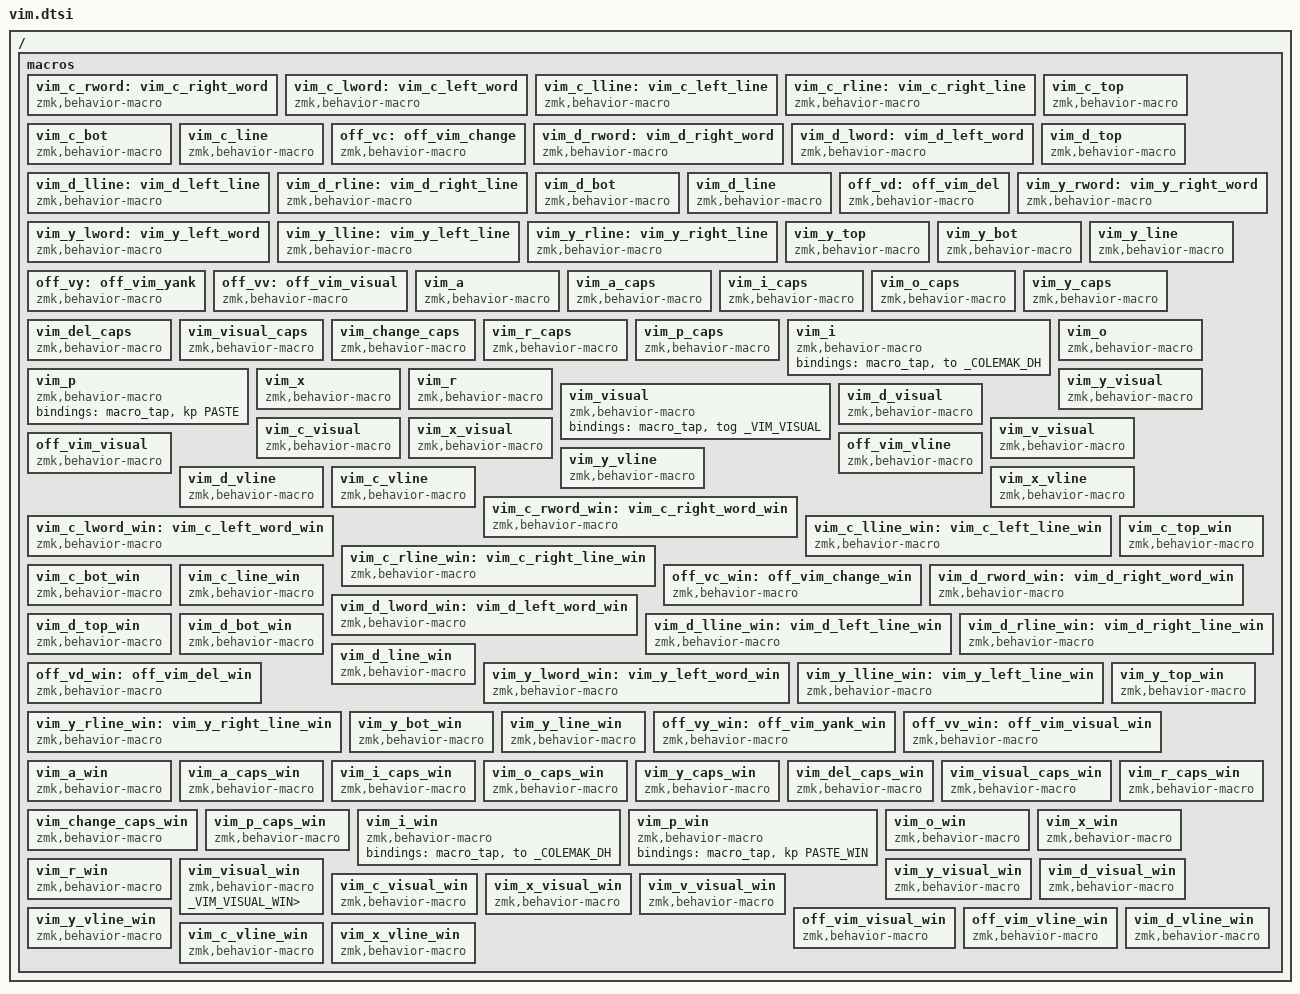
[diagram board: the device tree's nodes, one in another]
#define VLINE_UP LA(LS(UP))
#define VLINE_DOWN LA(LS(DOWN))

#define V_TOP LG(UP)
#define V_BOT LG(DOWN)

// WINDOWS vim section
#define SEARCH_WIN LC(F)

#define WORD_L_WIN LC(LEFT)
#define WORD_R_WIN LC(RIGHT)
#define WORD_L_SEL_WIN LC(LS(LEFT))
#define WORD_R_SEL_WIN LC(LS(RIGHT))

#define DEL_WORD_WIN LC(BSPC)
#define F_LINE_WIN HOME
#define L_LINE_WIN END

#define F_LINE_SEL_WIN LC(LS(HOME))
#define L_LINE_SEL_WIN LC(LS(END))

#define C_COPY_WIN LC(C)
#define PASTE_WIN LC(V)
#define C_CUT_WIN LC(X)
#define C_UNDO_WIN LC(Z)
#define C_REDO_WIN LC(LS(Z))

#define VLINE_UP_WIN LC(LS(UP))
#define VLINE_DOWN_WIN LC(LS(DOWN))

#define V_TOP_WIN LC(HOME)
#define V_BOT_WIN LC(END)
// end WINDOWS vim section

/ {

  macros {
  
    // vim CHANGE mode
    /omit-if-no-ref/ vim_c_rword: vim_c_right_word {
      wait-ms = <0>;
      tap-ms = <0>;
      compatible = "zmk,behavior-macro";
      #binding-cells = <0>;
      bindings = <&macro_tap &kp WORD_R_SEL>,
        <&macro_tap &kp BSPC>,
        <&macro_tap &to _COLEMAK_DH>;
    };

    /omit-if-no-ref/ vim_c_lword: vim_c_left_word {
      wait-ms = <0>;
      tap-ms = <0>;
      compatible = "zmk,behavior-macro";
      #binding-cells = <0>;
      bindings = <&macro_tap &kp WORD_L_SEL>,
        <&macro_tap &kp BSPC>,
        <&macro_tap &to _COLEMAK_DH>;
    };

    /omit-if-no-ref/ vim_c_lline: vim_c_left_line {
      wait-ms = <0>;
      tap-ms = <0>;
      compatible = "zmk,behavior-macro";
      #binding-cells = <0>;
      bindings = <&macro_tap &kp F_LINE_SEL>,
        <&macro_tap &kp BSPC>,
        <&macro_tap &to _COLEMAK_DH>;
    };

    /omit-if-no-ref/ vim_c_rline: vim_c_right_line {
      wait-ms = <0>;
      tap-ms = <0>;
      compatible = "zmk,behavior-macro";
      #binding-cells = <0>;
      bindings = <&macro_tap &kp L_LINE_SEL>,
        <&macro_tap &kp BSPC>,
        <&macro_tap &to _COLEMAK_DH>;
    };

    /omit-if-no-ref/ vim_c_top: vim_c_top {
      wait-ms = <0>;
      tap-ms = <0>;
      compatible = "zmk,behavior-macro";
      #binding-cells = <0>;
      bindings = <&macro_tap &kp VLINE_UP>,
        <&macro_tap &kp BSPC>,
        <&macro_tap &to _COLEMAK_DH>;
    };

    /omit-if-no-ref/ vim_c_bot: vim_c_bot {
      wait-ms = <0>;
      tap-ms = <0>;
      compatible = "zmk,behavior-macro";
      #binding-cells = <0>;
      bindings = <&macro_tap &kp VLINE_DOWN>,
        <&macro_tap &kp BSPC>,
        <&macro_tap &to _COLEMAK_DH>;
    };

    /omit-if-no-ref/ vim_c_line: vim_c_line {
      wait-ms = <0>;
      tap-ms = <0>;
      compatible = "zmk,behavior-macro";
      #binding-cells = <0>;
      bindings = <&macro_tap &kp F_LINE>,
        <&macro_tap &kp L_LINE_SEL>,
        <&macro_tap &kp BSPC>,
        <&macro_tap &to _COLEMAK_DH>;
    };

    /omit-if-no-ref/ off_vc: off_vim_change {
      wait-ms = <0>;
      tap-ms = <0>;
      compatible = "zmk,behavior-macro";
      #binding-cells = <0>;
      bindings = <&macro_tap &tog _VIM_CHANGE>;
    };

    // vim DEL mode
    /omit-if-no-ref/ vim_d_rword: vim_d_right_word {
      wait-ms = <0>;
      tap-ms = <0>;
      compatible = "zmk,behavior-macro";
      #binding-cells = <0>;
      bindings = <&macro_tap &kp WORD_R_SEL>,
        <&macro_tap &kp BSPC>;
    };

    /omit-if-no-ref/ vim_d_lword: vim_d_left_word {
      wait-ms = <0>;
      tap-ms = <0>;
      compatible = "zmk,behavior-macro";
      #binding-cells = <0>;
      bindings = <&macro_tap &kp WORD_L_SEL>,
        <&macro_tap &kp BSPC>;
    };

    /omit-if-no-ref/ vim_d_lline: vim_d_left_line {
      wait-ms = <0>;
      tap-ms = <0>;
      compatible = "zmk,behavior-macro";
      #binding-cells = <0>;
      bindings = <&macro_tap &kp F_LINE_SEL>,
        <&macro_tap &kp BSPC>;
    };

    /omit-if-no-ref/ vim_d_rline: vim_d_right_line {
      wait-ms = <0>;
      tap-ms = <0>;
      compatible = "zmk,behavior-macro";
      #binding-cells = <0>;
      bindings = <&macro_tap &kp L_LINE_SEL>,
        <&macro_tap &kp BSPC>;
    };

    /omit-if-no-ref/ vim_d_top: vim_d_top {
      wait-ms = <0>;
      tap-ms = <0>;
      compatible = "zmk,behavior-macro";
      #binding-cells = <0>;
      bindings = <&macro_tap &kp VLINE_UP>,
        <&macro_tap &kp BSPC>;
    };

    /omit-if-no-ref/ vim_d_bot: vim_d_bot {
      wait-ms = <0>;
      tap-ms = <0>;
      compatible = "zmk,behavior-macro";
      #binding-cells = <0>;
      bindings = <&macro_tap &kp VLINE_DOWN>,
        <&macro_tap &kp BSPC>;
    };


    /omit-if-no-ref/ vim_d_line: vim_d_line {
      wait-ms = <0>;
      tap-ms = <0>;
      compatible = "zmk,behavior-macro";
      #binding-cells = <0>;
      bindings = <&macro_tap &kp F_LINE>,
        <&macro_tap &kp L_LINE_SEL>,
        <&macro_tap &kp BSPC>;
    };

    /omit-if-no-ref/ off_vd: off_vim_del {
      wait-ms = <0>;
      tap-ms = <0>;
      compatible = "zmk,behavior-macro";
      #binding-cells = <0>;
      bindings = <&macro_tap &tog _VIM_DELETE>;
    };

    // vim YANK mode
    /omit-if-no-ref/ vim_y_rword: vim_y_right_word {
      wait-ms = <0>;
      tap-ms = <0>;
      compatible = "zmk,behavior-macro";
      #binding-cells = <0>;
      bindings = <&macro_tap &kp WORD_R_SEL>,
        <&macro_tap &kp C_COPY>,
        <&macro_tap &kp LEFT>;
    };

    /omit-if-no-ref/ vim_y_lword: vim_y_left_word {
      wait-ms = <0>;
      tap-ms = <0>;
      compatible = "zmk,behavior-macro";
      #binding-cells = <0>;
      bindings = <&macro_tap &kp WORD_L_SEL>,
        <&macro_tap &kp C_COPY>,
        <&macro_tap &kp LEFT>;
    };

    /omit-if-no-ref/ vim_y_lline: vim_y_left_line {
      wait-ms = <0>;
      tap-ms = <0>;
      compatible = "zmk,behavior-macro";
      #binding-cells = <0>;
      bindings = <&macro_tap &kp F_LINE_SEL>,
        <&macro_tap &kp C_COPY>,
        <&macro_tap &kp LEFT>;
    };

    /omit-if-no-ref/ vim_y_rline: vim_y_right_line {
      wait-ms = <0>;
      tap-ms = <0>;
      compatible = "zmk,behavior-macro";
      #binding-cells = <0>;
      bindings = <&macro_tap &kp L_LINE_SEL>,
        <&macro_tap &kp C_COPY>,
        <&macro_tap &kp LEFT>;
    };

    /omit-if-no-ref/ vim_y_top: vim_y_top {
      wait-ms = <0>;
      tap-ms = <0>;
      compatible = "zmk,behavior-macro";
      #binding-cells = <0>;
      bindings = <&macro_tap &kp VLINE_UP>,
        <&macro_tap &kp C_COPY>,
        <&macro_tap &kp LEFT>;
    };

    /omit-if-no-ref/ vim_y_bot: vim_y_bot {
      wait-ms = <0>;
      tap-ms = <0>;
      compatible = "zmk,behavior-macro";
      #binding-cells = <0>;
      bindings = <&macro_tap &kp VLINE_DOWN>,
        <&macro_tap &kp C_COPY>,
        <&macro_tap &kp LEFT>;
    };


    /omit-if-no-ref/ vim_y_line: vim_y_line {
      wait-ms = <0>;
      tap-ms = <0>;
      compatible = "zmk,behavior-macro";
      #binding-cells = <0>;
      bindings = <&macro_tap &kp F_LINE>,
        <&macro_tap &kp L_LINE_SEL>,
        <&macro_tap &kp C_COPY>,
        <&macro_tap &kp LEFT>;
    };

    /omit-if-no-ref/ off_vy: off_vim_yank {
      wait-ms = <0>;
      tap-ms = <0>;
      compatible = "zmk,behavior-macro";
      #binding-cells = <0>;
      bindings = <&macro_tap &tog _VIM_YANK>;
    };

    // vim VISUAL mode
    /omit-if-no-ref/ off_vv: off_vim_visual {
      wait-ms = <0>;
      tap-ms = <0>;
      compatible = "zmk,behavior-macro";
      #binding-cells = <0>;
      bindings = <&macro_tap &tog _VIM_VISUAL>;
    };


    /omit-if-no-ref/ vim_a: vim_a {
      compatible = "zmk,behavior-macro";
      #binding-cells = <0>;
      bindings 
      = <&macro_tap &kp RIGHT>
      ,<&macro_tap &to _COLEMAK_DH> 
      ;
    };

    /omit-if-no-ref/ vim_a_caps: vim_a_caps {
      compatible = "zmk,behavior-macro";
      #binding-cells = <0>;
      bindings 
      = <&macro_tap &kp L_LINE> 
      ,<&macro_tap &to _COLEMAK_DH> 
      ;
    };

    /omit-if-no-ref/ vim_i_caps: vim_i_caps {
      compatible = "zmk,behavior-macro";
      #binding-cells = <0>;
      bindings 
      = <&macro_tap &kp F_LINE> 
      ,<&macro_tap &to _COLEMAK_DH> 
      ;
    };

    /omit-if-no-ref/ vim_o_caps: vim_o_caps {
      compatible = "zmk,behavior-macro";
      #binding-cells = <0>;
      bindings 
      = <&macro_tap &kp F_LINE> 
      ,<&macro_tap &kp ENTER> 
      ,<&macro_tap &kp UP> 
      ,<&macro_tap &to _COLEMAK_DH> 
      ;
    };

    /omit-if-no-ref/ vim_y_caps: vim_y_caps {
      compatible = "zmk,behavior-macro";
      #binding-cells = <0>;
      bindings 
      = <&macro_tap &kp L_LINE_SEL> 
      ,<&macro_tap &kp C_COPY> 
      ,<&macro_tap &kp LEFT> 
      ;
    };

    /omit-if-no-ref/ vim_del_caps: vim_del_caps {
      compatible = "zmk,behavior-macro";
      #binding-cells = <0>;
      bindings 
      = <&macro_tap &kp L_LINE_SEL> 
      ,<&macro_tap &kp BSPC> 
      ;
    };

    /omit-if-no-ref/ vim_visual_caps: vim_visual_caps {
      compatible = "zmk,behavior-macro";
      #binding-cells = <0>;
      bindings = <&macro_tap &kp F_LINE>,
        <&macro_tap &kp L_LINE_SEL>,
        <&macro_tap &tog _VIM_VLINE>;
    };

    /omit-if-no-ref/ vim_change_caps: vim_change_caps {
      compatible = "zmk,behavior-macro";
      #binding-cells = <0>;
      bindings 
      = <&macro_tap &kp L_LINE_SEL> 
      ,<&macro_tap &kp BSPC> 
      ,<&macro_tap &to _COLEMAK_DH> 
      ;
    };

    /omit-if-no-ref/ vim_r_caps: vim_r_caps {
      compatible = "zmk,behavior-macro";
      #binding-cells = <0>;
      bindings 
      = <&macro_tap &kp INS> 
      ,<&macro_tap &to _COLEMAK_DH> 
      ;
    };

    /omit-if-no-ref/ vim_p_caps: vim_p_caps {
      compatible = "zmk,behavior-macro";
      #binding-cells = <0>;
      bindings 
      = <&macro_tap &kp F_LINE> 
      ,<&macro_tap &kp ENTER> 
      ,<&macro_tap &kp UP> 
      ,<&macro_tap &kp PASTE> 
      ;
    };

    /omit-if-no-ref/ vim_i: vim_i {
      compatible = "zmk,behavior-macro";
      #binding-cells = <0>;
      bindings 
      = <&macro_tap &to _COLEMAK_DH> 
      ;
    };

    /omit-if-no-ref/ vim_p: vim_p {
      compatible = "zmk,behavior-macro";
      #binding-cells = <0>;
      bindings 
      = <&macro_tap &kp PASTE> 
      ;
    };

    /omit-if-no-ref/ vim_o: vim_o {
      compatible = "zmk,behavior-macro";
      #binding-cells = <0>;
      bindings 
      = <&macro_tap &kp ENTER> 
      ,<&macro_tap &to _COLEMAK_DH> 
      ;
    };

    /omit-if-no-ref/ vim_x: vim_x {
      compatible = "zmk,behavior-macro";
      #binding-cells = <0>;
      bindings 
      = <&macro_tap &kp RIGHT>
      ,<&macro_tap &kp BSPC> 
      ;
    };

    /omit-if-no-ref/ vim_r: vim_r {
      compatible = "zmk,behavior-macro";
      #binding-cells = <0>;
      bindings 
      = <&macro_tap &kp RIGHT> 
      ,<&macro_tap &kp BSPC> 
      ,<&macro_tap &to _COLEMAK_DH> 
      ;
    };

    /omit-if-no-ref/ vim_visual: vim_visual {
      compatible = "zmk,behavior-macro";
      #binding-cells = <0>;
      bindings = <&macro_tap &tog _VIM_VISUAL>;
    };

    /omit-if-no-ref/ vim_y_visual: vim_y_visual {
      compatible = "zmk,behavior-macro";
      #binding-cells = <0>;
      bindings 
      = <&macro_tap &kp C_COPY>,
        <&macro_tap &kp LEFT>,
        <&macro_tap &tog _VIM_VISUAL>;
    };

    /omit-if-no-ref/ vim_d_visual: vim_d_visual {
      compatible = "zmk,behavior-macro";
      #binding-cells = <0>;
      bindings 
      = <&macro_tap &kp BSPC>,
        <&macro_tap &tog _VIM_VISUAL>;
    };

    /omit-if-no-ref/ vim_c_visual: vim_c_visual {
      compatible = "zmk,behavior-macro";
      #binding-cells = <0>;
      bindings 
      = <&macro_tap &kp BSPC>,
        <&macro_tap &to _COLEMAK_DH>;
    };

    /omit-if-no-ref/ vim_x_visual: vim_x_visual {
      compatible = "zmk,behavior-macro";
      #binding-cells = <0>;
      bindings 
      = <&macro_tap &kp C_CUT>,
        <&macro_tap &tog _VIM_VISUAL>;
    };

    /omit-if-no-ref/ vim_v_visual: vim_v_visual {
      compatible = "zmk,behavior-macro";
      #binding-cells = <0>;
      bindings 
      = <&macro_tap &kp LEFT>,
        <&macro_tap &kp RIGHT>,
        <&macro_tap &tog _VIM_VISUAL>;
    };

    /omit-if-no-ref/ off_vim_visual: off_vim_visual {
      compatible = "zmk,behavior-macro";
      #binding-cells = <0>;
      bindings 
      = <&macro_tap &kp LEFT>,
        <&macro_tap &kp RIGHT>,
        <&macro_tap &tog _VIM_VISUAL>;
    };

    /omit-if-no-ref/ off_vim_vline: off_vim_vline {
      compatible = "zmk,behavior-macro";
      #binding-cells = <0>;
      bindings 
      = <&macro_tap &kp LEFT>,
        <&macro_tap &kp RIGHT>,
        <&macro_tap &tog _VIM_VLINE>,
        <&macro_tap &tog _VIM_CAPS>;
    };

    /omit-if-no-ref/ vim_y_vline: vim_y_vline {
      compatible = "zmk,behavior-macro";
      #binding-cells = <0>;
      bindings 
      = <&macro_tap &kp C_COPY>,
        <&macro_tap &kp LEFT>,
        <&macro_tap &tog _VIM_VLINE>,
        <&macro_tap &tog _VIM_CAPS>;
    };

    /omit-if-no-ref/ vim_d_vline: vim_d_vline {
      compatible = "zmk,behavior-macro";
      #binding-cells = <0>;
      bindings 
      = <&macro_tap &kp DEL>,
        <&macro_tap &kp DEL>,
        <&macro_tap &tog _VIM_VLINE>,
        <&macro_tap &tog _VIM_CAPS>;
    };

    /omit-if-no-ref/ vim_c_vline: vim_c_vline {
      compatible = "zmk,behavior-macro";
      #binding-cells = <0>;
      bindings 
      = <&macro_tap &kp BSPC>,
        <&macro_tap &to _COLEMAK_DH>;
    };

    /omit-if-no-ref/ vim_x_vline: vim_x_vline {
      compatible = "zmk,behavior-macro";
      #binding-cells = <0>;
      bindings 
      = <&macro_tap &kp C_CUT>,
        <&macro_tap &tog _VIM_VLINE>,
        <&macro_tap &tog _VIM_CAPS>;
    };

    // WINDOWS VIM SECTION
    // vim WIN CHANGE mode
    /omit-if-no-ref/ vim_c_rword_win: vim_c_right_word_win {
      wait-ms = <0>;
      tap-ms = <0>;
      compatible = "zmk,behavior-macro";
      #binding-cells = <0>;
      bindings = <&macro_tap &kp WORD_R_SEL_WIN>,
        <&macro_tap &kp BSPC>,
        <&macro_tap &to _COLEMAK_DH>;
    };

    /omit-if-no-ref/ vim_c_lword_win: vim_c_left_word_win {
      wait-ms = <0>;
      tap-ms = <0>;
      compatible = "zmk,behavior-macro";
      #binding-cells = <0>;
      bindings = <&macro_tap &kp WORD_L_SEL_WIN>,
        <&macro_tap &kp BSPC>,
        <&macro_tap &to _COLEMAK_DH>;
    };

    /omit-if-no-ref/ vim_c_lline_win: vim_c_left_line_win {
      wait-ms = <0>;
      tap-ms = <0>;
      compatible = "zmk,behavior-macro";
      #binding-cells = <0>;
      bindings = <&macro_tap &kp F_LINE_SEL_WIN>,
        <&macro_tap &kp BSPC>,
        <&macro_tap &to _COLEMAK_DH>;
    };

    /omit-if-no-ref/ vim_c_rline_win: vim_c_right_line_win {
      wait-ms = <0>;
      tap-ms = <0>;
      compatible = "zmk,behavior-macro";
      #binding-cells = <0>;
      bindings = <&macro_tap &kp L_LINE_SEL_WIN>,
        <&macro_tap &kp BSPC>,
        <&macro_tap &to _COLEMAK_DH>;
    };

    /omit-if-no-ref/ vim_c_top_win: vim_c_top_win {
      wait-ms = <0>;
      tap-ms = <0>;
      compatible = "zmk,behavior-macro";
      #binding-cells = <0>;
      bindings = <&macro_tap &kp VLINE_UP_WIN>,
        <&macro_tap &kp BSPC>,
        <&macro_tap &to _COLEMAK_DH>;
    };

    /omit-if-no-ref/ vim_c_bot_win: vim_c_bot_win {
      wait-ms = <0>;
      tap-ms = <0>;
      compatible = "zmk,behavior-macro";
      #binding-cells = <0>;
      bindings = <&macro_tap &kp VLINE_DOWN_WIN>,
        <&macro_tap &kp BSPC>,
        <&macro_tap &to _COLEMAK_DH>;
    };

    /omit-if-no-ref/ vim_c_line_win: vim_c_line_win {
      wait-ms = <0>;
      tap-ms = <0>;
      compatible = "zmk,behavior-macro";
      #binding-cells = <0>;
      bindings = <&macro_tap &kp F_LINE_WIN>,
        <&macro_tap &kp L_LINE_SEL_WIN>,
        <&macro_tap &kp BSPC>,
        <&macro_tap &to _COLEMAK_DH>;
    };

    /omit-if-no-ref/ off_vc_win: off_vim_change_win {
      wait-ms = <0>;
      tap-ms = <0>;
      compatible = "zmk,behavior-macro";
      #binding-cells = <0>;
      bindings = <&macro_tap &tog _VIM_CHANGE_WIN>;
    };

    // vim DEL mode
    /omit-if-no-ref/ vim_d_rword_win: vim_d_right_word_win {
      wait-ms = <0>;
      tap-ms = <0>;
      compatible = "zmk,behavior-macro";
      #binding-cells = <0>;
      bindings = <&macro_tap &kp WORD_R_SEL_WIN>,
        <&macro_tap &kp BSPC>;
    };

    /omit-if-no-ref/ vim_d_lword_win: vim_d_left_word_win {
      wait-ms = <0>;
      tap-ms = <0>;
      compatible = "zmk,behavior-macro";
      #binding-cells = <0>;
      bindings = <&macro_tap &kp WORD_L_SEL_WIN>,
        <&macro_tap &kp BSPC>;
    };

    /omit-if-no-ref/ vim_d_lline_win: vim_d_left_line_win {
      wait-ms = <0>;
      tap-ms = <0>;
      compatible = "zmk,behavior-macro";
      #binding-cells = <0>;
      bindings = <&macro_tap &kp F_LINE_SEL_WIN>,
        <&macro_tap &kp BSPC>;
    };

    /omit-if-no-ref/ vim_d_rline_win: vim_d_right_line_win {
      wait-ms = <0>;
      tap-ms = <0>;
      compatible = "zmk,behavior-macro";
      #binding-cells = <0>;
      bindings = <&macro_tap &kp L_LINE_SEL_WIN>,
        <&macro_tap &kp BSPC>;
    };

    /omit-if-no-ref/ vim_d_top_win: vim_d_top_win {
      wait-ms = <0>;
      tap-ms = <0>;
      compatible = "zmk,behavior-macro";
      #binding-cells = <0>;
      bindings = <&macro_tap &kp VLINE_UP_WIN>,
        <&macro_tap &kp BSPC>;
    };

    /omit-if-no-ref/ vim_d_bot_win: vim_d_bot_win {
      wait-ms = <0>;
      tap-ms = <0>;
      compatible = "zmk,behavior-macro";
      #binding-cells = <0>;
      bindings = <&macro_tap &kp VLINE_DOWN_WIN>,
        <&macro_tap &kp BSPC>;
    };


    /omit-if-no-ref/ vim_d_line_win: vim_d_line_win {
      wait-ms = <0>;
      tap-ms = <0>;
      compatible = "zmk,behavior-macro";
      #binding-cells = <0>;
      bindings = <&macro_tap &kp F_LINE_WIN>,
        <&macro_tap &kp L_LINE_SEL_WIN>,
        <&macro_tap &kp BSPC>;
    };

    /omit-if-no-ref/ off_vd_win: off_vim_del_win {
      wait-ms = <0>;
      tap-ms = <0>;
      compatible = "zmk,behavior-macro";
      #binding-cells = <0>;
      bindings = <&macro_tap &tog _VIM_DELETE_WIN>;
    };

    // vim YANK mode
    /omit-if-no-ref/ vim_y_rword: vim_y_right_word {
      wait-ms = <0>;
      tap-ms = <0>;
      compatible = "zmk,behavior-macro";
      #binding-cells = <0>;
      bindings = <&macro_tap &kp WORD_R_SEL_WIN>,
        <&macro_tap &kp C_COPY_WIN>,
        <&macro_tap &kp LEFT>;
    };

    /omit-if-no-ref/ vim_y_lword_win: vim_y_left_word_win {
      wait-ms = <0>;
      tap-ms = <0>;
      compatible = "zmk,behavior-macro";
      #binding-cells = <0>;
      bindings = <&macro_tap &kp WORD_L_SEL_WIN>,
        <&macro_tap &kp C_COPY_WIN>,
        <&macro_tap &kp LEFT>;
    };

    /omit-if-no-ref/ vim_y_lline_win: vim_y_left_line_win {
      wait-ms = <0>;
      tap-ms = <0>;
      compatible = "zmk,behavior-macro";
      #binding-cells = <0>;
      bindings = <&macro_tap &kp F_LINE_SEL_WIN>,
        <&macro_tap &kp C_COPY_WIN>,
        <&macro_tap &kp LEFT>;
    };

    /omit-if-no-ref/ vim_y_rline_win: vim_y_right_line_win {
      wait-ms = <0>;
      tap-ms = <0>;
      compatible = "zmk,behavior-macro";
      #binding-cells = <0>;
      bindings = <&macro_tap &kp L_LINE_SEL_WIN>,
        <&macro_tap &kp C_COPY_WIN>,
        <&macro_tap &kp LEFT>;
    };

    /omit-if-no-ref/ vim_y_top_win: vim_y_top_win {
      wait-ms = <0>;
      tap-ms = <0>;
      compatible = "zmk,behavior-macro";
      #binding-cells = <0>;
      bindings = <&macro_tap &kp VLINE_UP_WIN>,
        <&macro_tap &kp C_COPY_WIN>,
        <&macro_tap &kp LEFT>;
    };

    /omit-if-no-ref/ vim_y_bot_win: vim_y_bot_win {
      wait-ms = <0>;
      tap-ms = <0>;
      compatible = "zmk,behavior-macro";
      #binding-cells = <0>;
      bindings = <&macro_tap &kp VLINE_DOWN_WIN>,
        <&macro_tap &kp C_COPY_WIN>,
        <&macro_tap &kp LEFT>;
    };


    /omit-if-no-ref/ vim_y_line_win: vim_y_line_win {
      wait-ms = <0>;
      tap-ms = <0>;
      compatible = "zmk,behavior-macro";
      #binding-cells = <0>;
      bindings = <&macro_tap &kp F_LINE_WIN>,
        <&macro_tap &kp L_LINE_SEL_WIN>,
        <&macro_tap &kp C_COPY_WIN>,
        <&macro_tap &kp LEFT>;
    };

    /omit-if-no-ref/ off_vy_win: off_vim_yank_win {
      wait-ms = <0>;
      tap-ms = <0>;
      compatible = "zmk,behavior-macro";
      #binding-cells = <0>;
      bindings = <&macro_tap &tog _VIM_YANK_WIN>;
    };

    // vim VISUAL mode
    /omit-if-no-ref/ off_vv_win: off_vim_visual_win {
      wait-ms = <0>;
      tap-ms = <0>;
      compatible = "zmk,behavior-macro";
      #binding-cells = <0>;
      bindings = <&macro_tap &tog _VIM_VISUAL_WIN>;
    };

    // end LATEST ADD achxi

    /omit-if-no-ref/ vim_a_win: vim_a_win {
      compatible = "zmk,behavior-macro";
      #binding-cells = <0>;
      bindings 
      = <&macro_tap &kp RIGHT> 
      ,<&macro_tap &to _COLEMAK_DH> 
      ;
    };

    /omit-if-no-ref/ vim_a_caps_win: vim_a_caps_win {
      compatible = "zmk,behavior-macro";
      #binding-cells = <0>;
      bindings 
      = <&macro_tap &kp L_LINE_WIN> 
      ,<&macro_tap &to _COLEMAK_DH> 
      ;
    };

    /omit-if-no-ref/ vim_i_caps_win: vim_i_caps_win {
      compatible = "zmk,behavior-macro";
      #binding-cells = <0>;
      bindings 
      = <&macro_tap &kp F_LINE_WIN> 
      ,<&macro_tap &to _COLEMAK_DH> 
      ;
    };

    /omit-if-no-ref/ vim_o_caps_win: vim_o_caps_win {
      compatible = "zmk,behavior-macro";
      #binding-cells = <0>;
      bindings 
      = <&macro_tap &kp F_LINE_WIN> 
      ,<&macro_tap &kp ENTER> 
      ,<&macro_tap &kp UP> 
      ,<&macro_tap &to _COLEMAK_DH> 
      ;
    };

    /omit-if-no-ref/ vim_y_caps_win: vim_y_caps_win {
      compatible = "zmk,behavior-macro";
      #binding-cells = <0>;
      bindings 
      = <&macro_tap &kp L_LINE_SEL_WIN> 
      ,<&macro_tap &kp C_COPY_WIN> 
      ,<&macro_tap &kp LEFT> 
      ;
    };

    /omit-if-no-ref/ vim_del_caps_win: vim_del_caps_win {
      compatible = "zmk,behavior-macro";
      #binding-cells = <0>;
      bindings 
      = <&macro_tap &kp L_LINE_SEL_WIN> 
      ,<&macro_tap &kp BSPC> 
      ;
    };

    /omit-if-no-ref/ vim_visual_caps_win: vim_visual_caps_win {
      compatible = "zmk,behavior-macro";
      #binding-cells = <0>;
      bindings = <&macro_tap &kp F_LINE_WIN>,
        <&macro_tap &kp L_LINE_SEL_WIN>,
        <&macro_tap &tog _VIM_VLINE_WIN>;
    };

    /omit-if-no-ref/ vim_change_caps_win: vim_change_caps_win {
      compatible = "zmk,behavior-macro";
      #binding-cells = <0>;
      bindings 
      = <&macro_tap &kp L_LINE_SEL_WIN> 
      ,<&macro_tap &kp BSPC> 
      ,<&macro_tap &to _COLEMAK_DH> 
      ;
    };

    /omit-if-no-ref/ vim_r_caps_win: vim_r_caps_win {
      compatible = "zmk,behavior-macro";
      #binding-cells = <0>;
      bindings 
      = <&macro_tap &kp INS> 
      ,<&macro_tap &to _COLEMAK_DH> 
      ;
    };

    /omit-if-no-ref/ vim_p_caps_win: vim_p_caps_win {
      compatible = "zmk,behavior-macro";
      #binding-cells = <0>;
      bindings 
      = <&macro_tap &kp F_LINE_WIN> 
      ,<&macro_tap &kp ENTER> 
      ,<&macro_tap &kp UP> 
      ,<&macro_tap &kp PASTE_WIN> 
      ;
    };

    /omit-if-no-ref/ vim_i_win: vim_i_win {
      compatible = "zmk,behavior-macro";
      #binding-cells = <0>;
      bindings 
      = <&macro_tap &to _COLEMAK_DH> 
      ;
    };

    /omit-if-no-ref/ vim_p_win: vim_p_win {
      compatible = "zmk,behavior-macro";
      #binding-cells = <0>;
      bindings 
      = <&macro_tap &kp PASTE_WIN> 
      ;
    };

    /omit-if-no-ref/ vim_o_win: vim_o_win {
      compatible = "zmk,behavior-macro";
      #binding-cells = <0>;
      bindings 
      = <&macro_tap &kp ENTER> 
      ,<&macro_tap &to _COLEMAK_DH> 
      ;
    };

    /omit-if-no-ref/ vim_x_win: vim_x_win {
      compatible = "zmk,behavior-macro";
      #binding-cells = <0>;
      bindings 
      = <&macro_tap &kp RIGHT>
      ,<&macro_tap &kp BSPC> 
      ;
    };

    /omit-if-no-ref/ vim_r_win: vim_r_win {
      compatible = "zmk,behavior-macro";
      #binding-cells = <0>;
      bindings 
      = <&macro_tap &kp RIGHT> 
      ,<&macro_tap &kp BSPC> 
      ,<&macro_tap &to _COLEMAK_DH> 
      ;
    };

    /omit-if-no-ref/ vim_visual_win: vim_visual_win {
      compatible = "zmk,behavior-macro";
      #binding-cells = <0>;
        <&macro_tap &tog _VIM_VISUAL_WIN>;
    };

    /omit-if-no-ref/ vim_y_visual_win: vim_y_visual_win {
      compatible = "zmk,behavior-macro";
      #binding-cells = <0>;
      bindings 
      = <&macro_tap &kp C_COPY_WIN>,
        <&macro_tap &kp LEFT>,
        <&macro_tap &tog _VIM_VISUAL_WIN>;
    };

    /omit-if-no-ref/ vim_d_visual_win: vim_d_visual_win {
      compatible = "zmk,behavior-macro";
      #binding-cells = <0>;
      bindings 
      = <&macro_tap &kp BSPC>,
        <&macro_tap &tog _VIM_VISUAL_WIN>;
    };

    /omit-if-no-ref/ vim_c_visual_win: vim_c_visual_win {
      compatible = "zmk,behavior-macro";
      #binding-cells = <0>;
      bindings 
      = <&macro_tap &kp BSPC>,
        <&macro_tap &to _COLEMAK_DH>;
    };

    /omit-if-no-ref/ vim_x_visual_win: vim_x_visual_win {
      compatible = "zmk,behavior-macro";
      #binding-cells = <0>;
      bindings 
      = <&macro_tap &kp C_CUT_WIN>,
        <&macro_tap &tog _VIM_VISUAL_WIN>;
    };

    /omit-if-no-ref/ vim_v_visual_win: vim_v_visual_win {
      compatible = "zmk,behavior-macro";
      #binding-cells = <0>;
      bindings 
      = <&macro_tap &kp LEFT>,
        <&macro_tap &kp RIGHT>,
        <&macro_tap &tog _VIM_VISUAL_WIN>;
    };

    /omit-if-no-ref/ off_vim_visual_win: off_vim_visual_win {
      compatible = "zmk,behavior-macro";
      #binding-cells = <0>;
      bindings 
      = <&macro_tap &kp LEFT>,
        <&macro_tap &kp RIGHT>,
        <&macro_tap &tog _VIM_VISUAL_WIN>;
    };

    /omit-if-no-ref/ off_vim_vline_win: off_vim_vline_win {
      compatible = "zmk,behavior-macro";
      #binding-cells = <0>;
      bindings 
      = <&macro_tap &kp LEFT>,
        <&macro_tap &kp RIGHT>,
        <&macro_tap &tog _VIM_VLINE_WIN>,
        <&macro_tap &tog _VIM_CAPS_WIN>;
    };

    /omit-if-no-ref/ vim_y_vline_win: vim_y_vline_win {
      compatible = "zmk,behavior-macro";
      #binding-cells = <0>;
      bindings 
      = <&macro_tap &kp C_COPY_WIN>,
        <&macro_tap &kp LEFT>,
        <&macro_tap &tog _VIM_VLINE_WIN>,
        <&macro_tap &tog _VIM_CAPS_WIN>;
    };

    /omit-if-no-ref/ vim_d_vline_win: vim_d_vline_win {
      compatible = "zmk,behavior-macro";
      #binding-cells = <0>;
      bindings 
      = <&macro_tap &kp DEL>,
        <&macro_tap &kp DEL>,
        <&macro_tap &tog _VIM_VLINE_WIN>,
        <&macro_tap &tog _VIM_CAPS_WIN>;
    };

    /omit-if-no-ref/ vim_c_vline_win: vim_c_vline_win {
      compatible = "zmk,behavior-macro";
      #binding-cells = <0>;
      bindings 
      = <&macro_tap &kp BSPC>,
        <&macro_tap &to _COLEMAK_DH>;
    };

    /omit-if-no-ref/ vim_x_vline_win: vim_x_vline_win {
      compatible = "zmk,behavior-macro";
      #binding-cells = <0>;
      bindings 
      = <&macro_tap &kp C_CUT_WIN>,
        <&macro_tap &tog _VIM_VLINE_WIN>,
        <&macro_tap &tog _VIM_CAPS_WIN>;
    };


    // END WINDOWS VIM SECTION

  };
};
